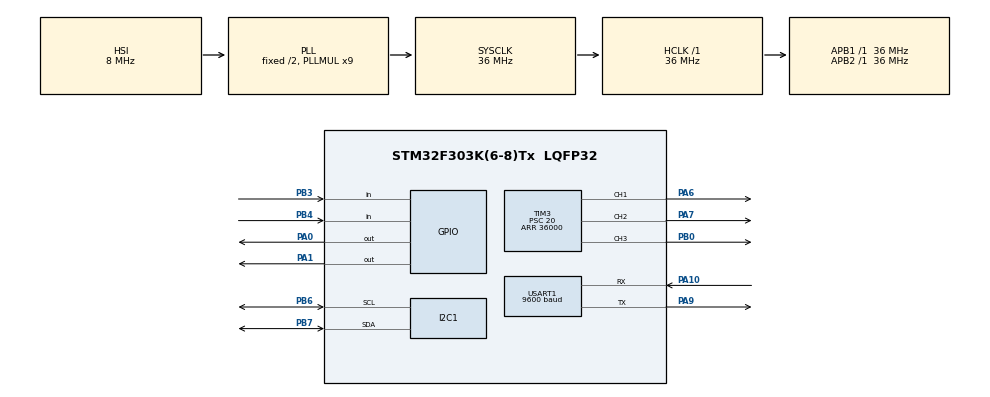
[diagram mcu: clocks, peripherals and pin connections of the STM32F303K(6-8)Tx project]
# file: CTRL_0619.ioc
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I2C1.I2C_Fall_Time=300
I2C1.I2C_Rise_Time=1000
I2C1.Speed=10
I2C1.Timing=0x40100794
Mcu.Family=STM32F3
Mcu.Name=STM32F303K(6-8)Tx
Mcu.Package=LQFP32
NVIC.I2C1_EV_IRQn=true\:0\:0\:false\:false\:true\:true\:true
NVIC.PriorityGroup=NVIC_PRIORITYGROUP_4
NVIC.USART1_IRQn=true\:0\:0\:false\:false\:true\:true\:true
PA0.Signal=GPIO_Output
PA1.Signal=GPIO_Output
PA10.Mode=Asynchronous
PA10.Signal=USART1_RX
PA13.Mode=Serial_Wire
PA13.Signal=SYS_JTMS-SWDIO
PA14.Mode=Serial_Wire
PA14.Signal=SYS_JTCK-SWCLK
PA6.GPIO_Speed=GPIO_SPEED_FREQ_MEDIUM
PA6.Signal=S_TIM3_CH1
PA7.GPIO_Speed=GPIO_SPEED_FREQ_MEDIUM
PA7.Signal=S_TIM3_CH2
PA9.Mode=Asynchronous
PA9.Signal=USART1_TX
PB0.GPIO_Speed=GPIO_SPEED_FREQ_MEDIUM
PB0.Signal=S_TIM3_CH3
PB3.GPIO_PuPd=GPIO_PULLUP
PB3.Signal=GPIO_Input
PB4.GPIO_PuPd=GPIO_PULLUP
PB4.Signal=GPIO_Input
PB6.Mode=I2C
PB6.Signal=I2C1_SCL
PB7.Mode=I2C
PB7.Signal=I2C1_SDA
ProjectManager.HeapSize=0x200
ProjectManager.StackSize=0x400
ProjectManager.TargetToolchain=STM32CubeIDE
RCC.AHBFreq_Value=36000000
RCC.APB1Freq_Value=36000000
RCC.APB1TimFreq_Value=36000000
RCC.APB2Freq_Value=36000000
RCC.APB2TimFreq_Value=36000000
RCC.CortexFreq_Value=36000000
RCC.HCLKFreq_Value=36000000
RCC.HSE_VALUE=8000000
RCC.HSI_VALUE=8000000
RCC.PLLMUL=RCC_PLL_MUL9
RCC.SYSCLKFreq_VALUE=36000000
RCC.SYSCLKSourceVirtual=RCC_SYSCLKSOURCE_PLLCLK
SH.S_TIM3_CH1.0=TIM3_CH1,PWM Generation1 CH1
SH.S_TIM3_CH2.0=TIM3_CH2,PWM Generation2 CH2
SH.S_TIM3_CH3.0=TIM3_CH3,PWM Generation3 CH3
TIM3.AutoReloadPreload=TIM_AUTORELOAD_PRELOAD_ENABLE
TIM3.Channel-PWM\ Generation1\ CH1=TIM_CHANNEL_1
TIM3.Channel-PWM\ Generation2\ CH2=TIM_CHANNEL_2
TIM3.Channel-PWM\ Generation3\ CH3=TIM_CHANNEL_3
TIM3.OCPolarity_1=TIM_OCPOLARITY_LOW
TIM3.OCPolarity_2=TIM_OCPOLARITY_LOW
TIM3.OCPolarity_3=TIM_OCPOLARITY_LOW
TIM3.Period=36000
TIM3.Prescaler=20
TIM3.Pulse-PWM\ Generation1\ CH1=3000
TIM3.Pulse-PWM\ Generation2\ CH2=3000
TIM3.Pulse-PWM\ Generation3\ CH3=3000
USART1.BaudRate=9600
USART1.VirtualMode-Asynchronous=VM_ASYNC
VP_TIM3_VS_ClockSourceINT.Mode=Internal
board=custom

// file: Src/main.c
/* USER CODE BEGIN Header */
/**
 ******************************************************************************
 * @file           : main.c
 * @brief          : Main program body
 ******************************************************************************
 * @attention
 *
 * <h2><center>&copy; Copyright (c) 2019 STMicroelectronics.
 * All rights reserved.</center></h2>
 *
 * This software component is licensed by ST under BSD 3-Clause license,
 * the "License"; You may not use this file except in compliance with the
 * License. You may obtain a copy of the License at:
 *                        opensource.org/licenses/BSD-3-Clause
 *
 ******************************************************************************
 */
/* USER CODE END Header */

#include "main.h"

void SystemClock_Config(void);
static void MX_GPIO_Init(void);
static void MX_I2C1_Init(void);
static void MX_USART1_UART_Init(void);
static void MX_TIM3_Init(void);

int main(void) {

	/* MCU Configuration--------------------------------------------------------*/

	/* Reset of all peripherals, Initializes the Flash interface and the Systick. */
	HAL_Init();

	/* Configure the system clock */
	SystemClock_Config();

	/* Initialize all configured peripherals */
	MX_GPIO_Init();
	MX_I2C1_Init();
	MX_USART1_UART_Init();
	MX_TIM3_Init();

	/* Infinite loop */
	while (1) {

	}
}

void SystemClock_Config(void) {
	RCC_OscInitTypeDef RCC_OscInitStruct = { 0 };
	RCC_ClkInitTypeDef RCC_ClkInitStruct = { 0 };
	RCC_PeriphCLKInitTypeDef PeriphClkInit = { 0 };

	/** Initializes the CPU, AHB and APB busses clocks
	 */
	RCC_OscInitStruct.OscillatorType = RCC_OSCILLATORTYPE_HSI;
	RCC_OscInitStruct.HSIState = RCC_HSI_ON;
	RCC_OscInitStruct.HSICalibrationValue = RCC_HSICALIBRATION_DEFAULT;
	RCC_OscInitStruct.PLL.PLLState = RCC_PLL_ON;
	RCC_OscInitStruct.PLL.PLLSource = RCC_PLLSOURCE_HSI;
	RCC_OscInitStruct.PLL.PLLMUL = RCC_PLL_MUL9;
	if (HAL_RCC_OscConfig(&RCC_OscInitStruct) != HAL_OK) {
		Error_Handler();
	}
	/** Initializes the CPU, AHB and APB busses clocks
	 */
	RCC_ClkInitStruct.ClockType = RCC_CLOCKTYPE_HCLK | RCC_CLOCKTYPE_SYSCLK
			| RCC_CLOCKTYPE_PCLK1 | RCC_CLOCKTYPE_PCLK2;
	RCC_ClkInitStruct.SYSCLKSource = RCC_SYSCLKSOURCE_PLLCLK;
	RCC_ClkInitStruct.AHBCLKDivider = RCC_SYSCLK_DIV1;
	RCC_ClkInitStruct.APB1CLKDivider = RCC_HCLK_DIV1;
	RCC_ClkInitStruct.APB2CLKDivider = RCC_HCLK_DIV1;

	if (HAL_RCC_ClockConfig(&RCC_ClkInitStruct, FLASH_LATENCY_1) != HAL_OK) {
		Error_Handler();
	}
	PeriphClkInit.PeriphClockSelection = RCC_PERIPHCLK_USART1
			| RCC_PERIPHCLK_I2C1;
	PeriphClkInit.Usart1ClockSelection = RCC_USART1CLKSOURCE_PCLK1;
	PeriphClkInit.I2c1ClockSelection = RCC_I2C1CLKSOURCE_HSI;
	if (HAL_RCCEx_PeriphCLKConfig(&PeriphClkInit) != HAL_OK) {
		Error_Handler();
	}
}

static void MX_I2C1_Init(void) {

	LL_I2C_InitTypeDef I2C_InitStruct = { 0 };

	LL_GPIO_InitTypeDef GPIO_InitStruct = { 0 };

	LL_AHB1_GRP1_EnableClock(LL_AHB1_GRP1_PERIPH_GPIOB);
	/**I2C1 GPIO Configuration
	 PB6   ------> I2C1_SCL
	 PB7   ------> I2C1_SDA
	 */
	GPIO_InitStruct.Pin = LL_GPIO_PIN_6 | LL_GPIO_PIN_7;
	GPIO_InitStruct.Mode = LL_GPIO_MODE_ALTERNATE;
	GPIO_InitStruct.Speed = LL_GPIO_SPEED_FREQ_HIGH;
	GPIO_InitStruct.OutputType = LL_GPIO_OUTPUT_OPENDRAIN;
	GPIO_InitStruct.Pull = LL_GPIO_PULL_UP;
	GPIO_InitStruct.Alternate = LL_GPIO_AF_4;
	LL_GPIO_Init(GPIOB, &GPIO_InitStruct);

	/* Peripheral clock enable */
	LL_APB1_GRP1_EnableClock(LL_APB1_GRP1_PERIPH_I2C1);

	/* I2C1 interrupt Init */
	NVIC_SetPriority(I2C1_EV_IRQn,
			NVIC_EncodePriority(NVIC_GetPriorityGrouping(), 0, 0));
	NVIC_EnableIRQ(I2C1_EV_IRQn);

	/** I2C Initialization
	 */
	LL_I2C_EnableAutoEndMode(I2C1);
	LL_I2C_DisableOwnAddress2(I2C1);
	LL_I2C_DisableGeneralCall(I2C1);
	LL_I2C_EnableClockStretching(I2C1);
	I2C_InitStruct.PeripheralMode = LL_I2C_MODE_I2C;
	I2C_InitStruct.Timing = 0x40100794;
	I2C_InitStruct.AnalogFilter = LL_I2C_ANALOGFILTER_ENABLE;
	I2C_InitStruct.DigitalFilter = 0;
	I2C_InitStruct.OwnAddress1 = 0;
	I2C_InitStruct.TypeAcknowledge = LL_I2C_ACK;
	I2C_InitStruct.OwnAddrSize = LL_I2C_OWNADDRESS1_7BIT;
	LL_I2C_Init(I2C1, &I2C_InitStruct);
	LL_I2C_SetOwnAddress2(I2C1, 0, LL_I2C_OWNADDRESS2_NOMASK);

}

static void MX_TIM3_Init(void) {

	LL_TIM_InitTypeDef TIM_InitStruct = { 0 };
	LL_TIM_OC_InitTypeDef TIM_OC_InitStruct = { 0 };

	LL_GPIO_InitTypeDef GPIO_InitStruct = { 0 };

	/* Peripheral clock enable */
	LL_APB1_GRP1_EnableClock(LL_APB1_GRP1_PERIPH_TIM3);

	TIM_InitStruct.Prescaler = 20;
	TIM_InitStruct.CounterMode = LL_TIM_COUNTERMODE_UP;
	TIM_InitStruct.Autoreload = 36000;
	TIM_InitStruct.ClockDivision = LL_TIM_CLOCKDIVISION_DIV1;
	LL_TIM_Init(TIM3, &TIM_InitStruct);
	LL_TIM_EnableARRPreload(TIM3);
	LL_TIM_SetClockSource(TIM3, LL_TIM_CLOCKSOURCE_INTERNAL);
	LL_TIM_OC_EnablePreload(TIM3, LL_TIM_CHANNEL_CH1);
	TIM_OC_InitStruct.OCMode = LL_TIM_OCMODE_PWM1;
	TIM_OC_InitStruct.OCState = LL_TIM_OCSTATE_ENABLE;
	TIM_OC_InitStruct.OCNState = LL_TIM_OCSTATE_DISABLE;
	TIM_OC_InitStruct.CompareValue = 3000;
	TIM_OC_InitStruct.OCPolarity = LL_TIM_OCPOLARITY_LOW;
	LL_TIM_OC_Init(TIM3, LL_TIM_CHANNEL_CH1, &TIM_OC_InitStruct);
	LL_TIM_OC_DisableFast(TIM3, LL_TIM_CHANNEL_CH1);
	LL_TIM_OC_EnablePreload(TIM3, LL_TIM_CHANNEL_CH2);
	TIM_OC_InitStruct.OCState = LL_TIM_OCSTATE_ENABLE;
	TIM_OC_InitStruct.OCNState = LL_TIM_OCSTATE_DISABLE;
	LL_TIM_OC_Init(TIM3, LL_TIM_CHANNEL_CH2, &TIM_OC_InitStruct);
	LL_TIM_OC_DisableFast(TIM3, LL_TIM_CHANNEL_CH2);
	LL_TIM_OC_EnablePreload(TIM3, LL_TIM_CHANNEL_CH3);
	TIM_OC_InitStruct.OCState = LL_TIM_OCSTATE_ENABLE;
	TIM_OC_InitStruct.OCNState = LL_TIM_OCSTATE_DISABLE;
	LL_TIM_OC_Init(TIM3, LL_TIM_CHANNEL_CH3, &TIM_OC_InitStruct);
	LL_TIM_OC_DisableFast(TIM3, LL_TIM_CHANNEL_CH3);
	LL_TIM_SetTriggerOutput(TIM3, LL_TIM_TRGO_RESET);
	LL_TIM_DisableMasterSlaveMode(TIM3);
	/* USER CODE BEGIN TIM3_Init 2 */
	LL_TIM_EnableCounter(TIM3);
	LL_TIM_EnableAllOutputs(TIM3);

	/* USER CODE END TIM3_Init 2 */
	LL_AHB1_GRP1_EnableClock(LL_AHB1_GRP1_PERIPH_GPIOA);
	LL_AHB1_GRP1_EnableClock(LL_AHB1_GRP1_PERIPH_GPIOB);
	/**TIM3 GPIO Configuration
	 PA6   ------> TIM3_CH1
	 PA7   ------> TIM3_CH2
	 PB0   ------> TIM3_CH3
	 */
	GPIO_InitStruct.Pin = LL_GPIO_PIN_6 | LL_GPIO_PIN_7;
	GPIO_InitStruct.Mode = LL_GPIO_MODE_ALTERNATE;
	GPIO_InitStruct.Speed = LL_GPIO_SPEED_FREQ_MEDIUM;
	GPIO_InitStruct.OutputType = LL_GPIO_OUTPUT_PUSHPULL;
	GPIO_InitStruct.Pull = LL_GPIO_PULL_NO;
	GPIO_InitStruct.Alternate = LL_GPIO_AF_2;
	LL_GPIO_Init(GPIOA, &GPIO_InitStruct);

	GPIO_InitStruct.Pin = LL_GPIO_PIN_0;
	GPIO_InitStruct.Mode = LL_GPIO_MODE_ALTERNATE;
	GPIO_InitStruct.Speed = LL_GPIO_SPEED_FREQ_MEDIUM;
	GPIO_InitStruct.OutputType = LL_GPIO_OUTPUT_PUSHPULL;
	GPIO_InitStruct.Pull = LL_GPIO_PULL_NO;
	GPIO_InitStruct.Alternate = LL_GPIO_AF_2;
	LL_GPIO_Init(GPIOB, &GPIO_InitStruct);

}

static void MX_USART1_UART_Init(void) {

	LL_USART_InitTypeDef USART_InitStruct = { 0 };

	LL_GPIO_InitTypeDef GPIO_InitStruct = { 0 };

	/* Peripheral clock enable */
	LL_APB2_GRP1_EnableClock(LL_APB2_GRP1_PERIPH_USART1);

	LL_AHB1_GRP1_EnableClock(LL_AHB1_GRP1_PERIPH_GPIOA);
	/**USART1 GPIO Configuration
	 PA9   ------> USART1_TX
	 PA10   ------> USART1_RX
	 */
	GPIO_InitStruct.Pin = LL_GPIO_PIN_9 | LL_GPIO_PIN_10;
	GPIO_InitStruct.Mode = LL_GPIO_MODE_ALTERNATE;
	GPIO_InitStruct.Speed = LL_GPIO_SPEED_FREQ_HIGH;
	GPIO_InitStruct.OutputType = LL_GPIO_OUTPUT_PUSHPULL;
	GPIO_InitStruct.Pull = LL_GPIO_PULL_NO;
	GPIO_InitStruct.Alternate = LL_GPIO_AF_7;
	LL_GPIO_Init(GPIOA, &GPIO_InitStruct);

	/* USART1 interrupt Init */
	NVIC_SetPriority(USART1_IRQn,
			NVIC_EncodePriority(NVIC_GetPriorityGrouping(), 0, 0));
	NVIC_EnableIRQ(USART1_IRQn);

	USART_InitStruct.BaudRate = 9600;
	USART_InitStruct.DataWidth = LL_USART_DATAWIDTH_8B;
	USART_InitStruct.StopBits = LL_USART_STOPBITS_1;
	USART_InitStruct.Parity = LL_USART_PARITY_NONE;
	USART_InitStruct.TransferDirection = LL_USART_DIRECTION_TX_RX;
	USART_InitStruct.HardwareFlowControl = LL_USART_HWCONTROL_NONE;
	USART_InitStruct.OverSampling = LL_USART_OVERSAMPLING_16;
	LL_USART_Init(USART1, &USART_InitStruct);
	LL_USART_DisableIT_CTS(USART1);
	LL_USART_ConfigAsyncMode(USART1);
	LL_USART_Enable(USART1);
	/* USER CODE BEGIN USART1_Init 2 */
	/* USART1 interrupt*/
	//LL_USART_EnableIT_RXNE(USART1);
	/* USER CODE END USART1_Init 2 */

}

static void MX_GPIO_Init(void) {
	LL_GPIO_InitTypeDef GPIO_InitStruct = { 0 };

	/* GPIO Ports Clock Enable */
	LL_AHB1_GRP1_EnableClock(LL_AHB1_GRP1_PERIPH_GPIOA);
	LL_AHB1_GRP1_EnableClock(LL_AHB1_GRP1_PERIPH_GPIOB);

	/**/
	LL_GPIO_ResetOutputPin(GPIOA, LL_GPIO_PIN_0 | LL_GPIO_PIN_1);

	/**/
	GPIO_InitStruct.Pin = LL_GPIO_PIN_0 | LL_GPIO_PIN_1;
	GPIO_InitStruct.Mode = LL_GPIO_MODE_OUTPUT;
	GPIO_InitStruct.Speed = LL_GPIO_SPEED_FREQ_LOW;
	GPIO_InitStruct.OutputType = LL_GPIO_OUTPUT_PUSHPULL;
	GPIO_InitStruct.Pull = LL_GPIO_PULL_NO;
	LL_GPIO_Init(GPIOA, &GPIO_InitStruct);

	/**/
	GPIO_InitStruct.Pin = LL_GPIO_PIN_3 | LL_GPIO_PIN_4;
	GPIO_InitStruct.Mode = LL_GPIO_MODE_INPUT;
	GPIO_InitStruct.Pull = LL_GPIO_PULL_UP;
	LL_GPIO_Init(GPIOB, &GPIO_InitStruct);

}

void Error_Handler(void) {
}

/************************ (C) COPYRIGHT STMicroelectronics *****END OF FILE****/
